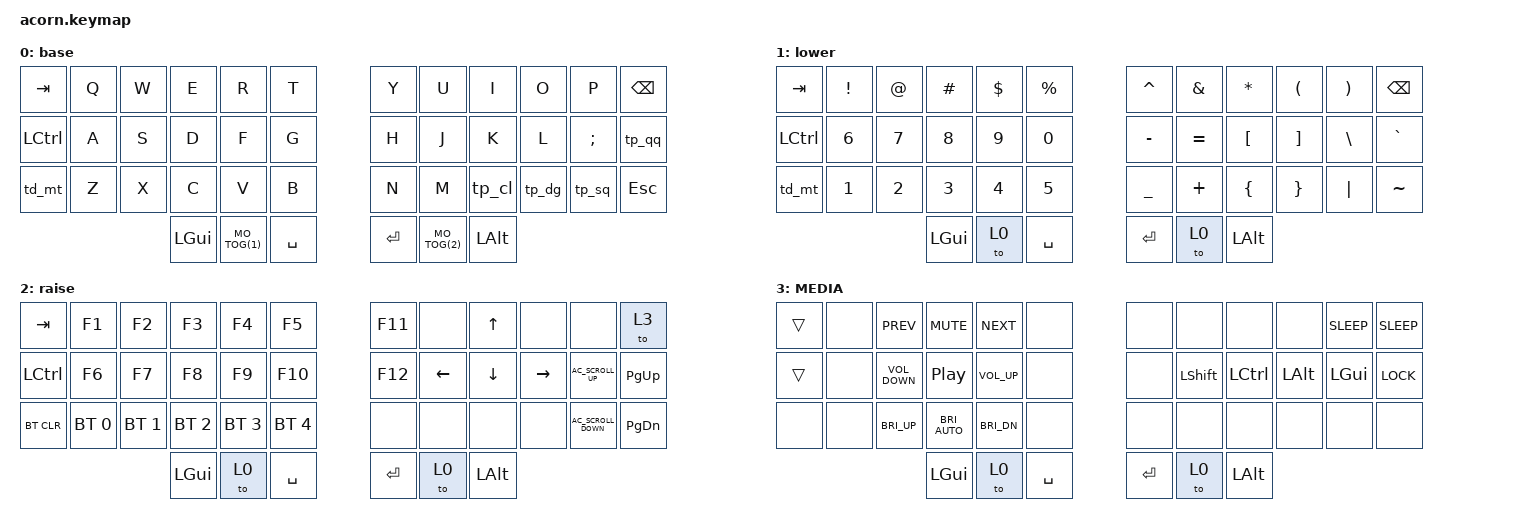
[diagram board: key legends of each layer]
#include <behaviors.dtsi>
#include <dt-bindings/zmk/keys.h>
#include <dt-bindings/zmk/bt.h>

#define MO_TOG(layer) &mo_tog layer layer   // Macro to apply momentary-layer-on-hold/toggle-layer-on-tap to a specific layer

/ {

    combos {
        compatible = "zmk,combos";

        combo_studio_unlock {
            timeout-ms = <50>;
            key-positions = <0 1>;
            bindings = <&studio_unlock>;
        };
    };

    behaviors {
        mo_tog: behavior_mo_tog {
            compatible = "zmk,behavior-hold-tap";
            #binding-cells = <2>;
            flavor = "hold-preferred";
            tapping-term-ms = <200>;
            bindings = <&mo>, <&tog>;
        };

        tp_qq: tapdance_0 {
            compatible = "zmk,behavior-tap-dance";
            #binding-cells = <0>;
            tapping-term-ms = <200>;
            bindings = <&kp SQT>, <&kp DQT>;
        };

        tp_cl: tapdance_1 {
            compatible = "zmk,behavior-tap-dance";
            #binding-cells = <0>;
            tapping-term-ms = <200>;
            bindings = <&kp COMMA>, <&kp LT>;
        };

        tp_dg: tapdance_2 {
            compatible = "zmk,behavior-tap-dance";
            #binding-cells = <0>;
            tapping-term-ms = <200>;
            bindings = <&kp DOT>, <&kp GT>;
        };

        tp_sq: tapdance_3 {
            compatible = "zmk,behavior-tap-dance";
            #binding-cells = <0>;
            tapping-term-ms = <200>;
            bindings = <&kp FSLH>, <&kp QMARK>;
        };

        td_mt: tap_dance_mod_tap {
            compatible = "zmk,behavior-tap-dance";
            #binding-cells = <0>;
            tapping-term-ms = <200>;
            bindings = <&mt LSHIFT CAPSLOCK>, <&kp LCTRL>;
        };
    };

    keymap {
        compatible = "zmk,keymap";

        default_layer {
            display-name = "base";
            sensor-bindings = <&inc_dec_kp C_VOL_UP C_VOL_DN &inc_dec_kp C_VOL_UP C_VOL_DN>;
// -----------------------------------------------------------------------------------------
// |  TAB |  Q  |  W  |  E  |  R  |  T  |   |  Y  |  U   |  I  |  O  |  P  | BSPC |
// | CTRL |  A  |  S  |  D  |  F  |  G  |   |  H  |  J   |  K  |  L  |  ;  |  '   |
// | SHFT |  Z  |  X  |  C  |  V  |  B  |   |  N  |  M   |  ,  |  .  |  /  | ESC  |
//                    | GUI | LWR | SPC |   | ENT | RSE  | ALT |
            bindings = < 
&kp TAB     &kp Q   &kp W       &kp E       &kp R       &kp T                               &kp Y   &kp U     &kp I   &kp O    &kp P     &kp BSPC
&kp LCTRL   &kp A   &kp S       &kp D       &kp F       &kp G                               &kp H   &kp J     &kp K   &kp L    &kp SEMI  &tp_qq
&td_mt      &kp Z   &kp X       &kp C       &kp V       &kp B                               &kp N   &kp M     &tp_cl  &tp_dg   &tp_sq    &kp ESC
                                &kp LGUI    MO_TOG(1)   &kp SPACE                           &kp RET MO_TOG(2) &kp LALT
            >;
        };

        lower_layer {
            display-name = "lower";
// -----------------------------------------------------------------------------------------
// |  TAB |  !  |  @  |  #  |  $  |  %  |   |  ^  |  &  |  *  |  (  |  )  | BSPC |
// |      |  6  |  7  |  8  |  9  |  0  |   |  -  |  =  |  [  |  ]  |  \  |  `   |
// | SHFT |  1  |  2  |  3  |  4  |  5  |   |  _  |  +  |  {  |  }  | "|" |  ~   |
//                    | GUI |tog 0| SPC |   | ENT |     | ALT |
            bindings = <
&kp TAB    &kp EXCL     &kp AT       &kp HASH     &kp DLLR     &kp PRCNT                    &kp CARET     &kp AMPS      &kp ASTRK   &kp LPAR    &kp RPAR    &kp BSPC
&kp LCTRL  &kp N6       &kp N7       &kp N8       &kp N9       &kp N0                       &kp MINUS     &kp EQUAL     &kp LBKT    &kp RBKT    &kp BSLH    &kp GRAVE
&td_mt     &kp N1       &kp N2       &kp N3       &kp N4       &kp N5                       &kp UNDER     &kp PLUS      &kp LBRC    &kp RBRC    &kp PIPE    &kp TILDE
                                     &kp LGUI     &to 0        &kp SPACE                    &kp RET       &to 0         &kp LALT
            >;
        };

        raise_layer {
            display-name = "raise";
// -----------------------------------------------------------------------------------------
// |  TAB |  F1 |  F2 |  F3 |  F4 |  F5 |   | F11 |     |  UP |     |     | BSPC |
// | CTRL |  F6 |  F7 |  F8 |  F9 | F10 |   | F12 | LEFT| DOWN| RGT |     |      |
// | BTCLR| BT1 | BT2 | BT3 | BT4 | BT5 |   |     | CAPS|     |     |     |      |
//                    | GUI |     | SPC |   | ENT |tog 0| ALT |
            bindings = <
&kp TAB     &kp F1       &kp F2       &kp F3       &kp F4       &kp F5                      &kp F11        &none            &kp UP       &none        &none                 &to 3 
&kp LCTRL   &kp F6       &kp F7       &kp F8       &kp F9       &kp F10                     &kp F12        &kp LEFT         &kp DOWN     &kp RIGHT    &kp C_AC_SCROLL_UP    &kp PG_UP
&bt BT_CLR  &bt BT_SEL 0 &bt BT_SEL 1 &bt BT_SEL 2 &bt BT_SEL 3 &bt BT_SEL 4                &none          &none            &none        &none        &kp C_AC_SCROLL_DOWN   &kp PG_DN
                                      &kp LGUI     &to 0        &kp SPACE                   &kp RET        &to 0            &kp LALT
            >;
        };

        media {
            display-name = "MEDIA";
            bindings = <
&trans  &none  &kp C_PREV         &kp C_MUTE        &kp C_NEXT       &none                  &none     &none           &none             &none         &kp K_SLEEP   &kp C_SLEEP
&trans  &none  &kp C_VOLUME_DOWN  &kp C_PLAY_PAUSE  &kp C_VOLUME_UP  &none                  &none     &kp LEFT_SHIFT  &kp LEFT_CONTROL  &kp LEFT_ALT  &kp LEFT_GUI  &kp K_LOCK
&none   &none  &kp C_BRI_UP       &kp C_BRI_AUTO    &kp C_BRI_DN     &none                  &none     &none           &none             &none         &none         &none
                                  &kp LGUI          &to 0            &kp SPACE              &kp RET   &to 0           &kp LALT
            >;
        };

        extra_layer1 {
            display-name = "extra_layer1";
            status = "reserved";
        };

        extra_layer2 {
            display-name = "extra_layer2";
            status = "reserved";
        };
    };
};
